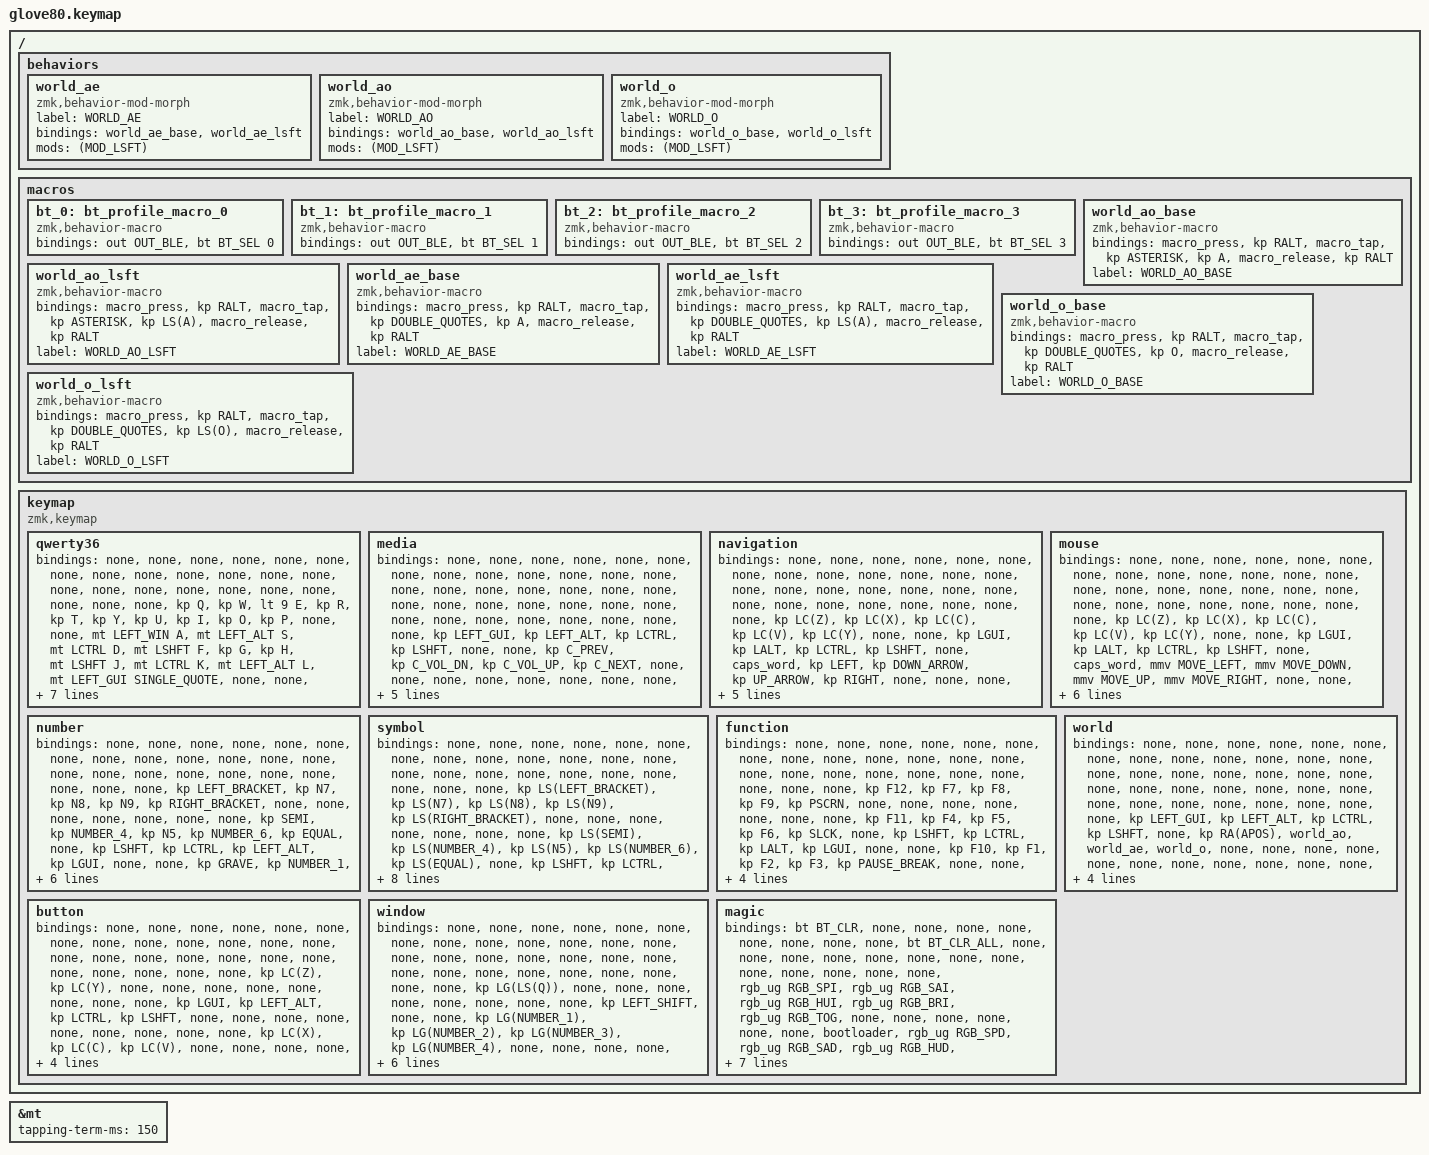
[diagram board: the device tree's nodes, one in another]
/*
 * Copyright (c) 2020 The ZMK Contributors
 *
 * SPDX-License-Identifier: MIT
 */

#include <behaviors.dtsi>
#include <dt-bindings/zmk/bt.h>
#include <dt-bindings/zmk/keys.h>
#include <dt-bindings/zmk/outputs.h>
#include <dt-bindings/zmk/pointing.h>
#include <dt-bindings/zmk/rgb.h>

// layers

#define DEFAULT 0
#define LOWER 1
#define MAGIC 2

&mt { tapping-term-ms = <150>; };

/ {
    behaviors {
        // For the "layer" key, it'd nice to be able to use it as either a shift or a toggle.
        // Configure it as a tap dance, so the first tap (or hold) is a &mo and the second tap is a &to

        world_ae: world_ae {
            compatible = "zmk,behavior-mod-morph";
            label = "WORLD_AE";
            bindings = <&world_ae_base>, <&world_ae_lsft>;

            #binding-cells = <0>;
            mods = <(MOD_LSFT)>;
        };

        world_ao: world_ao {
            compatible = "zmk,behavior-mod-morph";
            label = "WORLD_AO";
            bindings = <&world_ao_base>, <&world_ao_lsft>;

            #binding-cells = <0>;
            mods = <(MOD_LSFT)>;
        };

        world_o: world_o {
            compatible = "zmk,behavior-mod-morph";
            label = "WORLD_O";
            bindings = <&world_o_base>, <&world_o_lsft>;

            #binding-cells = <0>;
            mods = <(MOD_LSFT)>;
        };
    };

    macros {
        bt_0: bt_profile_macro_0 {
            compatible = "zmk,behavior-macro";
            #binding-cells = <0>;
            bindings = <&out OUT_BLE &bt BT_SEL 0>;
        };

        bt_1: bt_profile_macro_1 {
            compatible = "zmk,behavior-macro";
            #binding-cells = <0>;
            bindings = <&out OUT_BLE &bt BT_SEL 1>;
        };

        bt_2: bt_profile_macro_2 {
            compatible = "zmk,behavior-macro";
            #binding-cells = <0>;
            bindings = <&out OUT_BLE &bt BT_SEL 2>;
        };

        bt_3: bt_profile_macro_3 {
            compatible = "zmk,behavior-macro";
            #binding-cells = <0>;
            bindings = <&out OUT_BLE &bt BT_SEL 3>;
        };

        world_ao_base: world_ao_base {
            compatible = "zmk,behavior-macro";
            #binding-cells = <0>;
            bindings =
                <&macro_press>,
                <&kp RALT>,
                <&macro_tap>,
                <&kp ASTERISK &kp A>,
                <&macro_release>,
                <&kp RALT>;

            label = "WORLD_AO_BASE";
        };

        world_ao_lsft: world_ao_lsft {
            compatible = "zmk,behavior-macro";
            #binding-cells = <0>;
            bindings =
                <&macro_press>,
                <&kp RALT>,
                <&macro_tap>,
                <&kp ASTERISK &kp LS(A)>,
                <&macro_release>,
                <&kp RALT>;

            label = "WORLD_AO_LSFT";
        };

        world_ae_base: world_ae_base {
            compatible = "zmk,behavior-macro";
            #binding-cells = <0>;
            bindings =
                <&macro_press>,
                <&kp RALT>,
                <&macro_tap>,
                <&kp DOUBLE_QUOTES &kp A>,
                <&macro_release>,
                <&kp RALT>;

            label = "WORLD_AE_BASE";
        };

        world_ae_lsft: world_ae_lsft {
            compatible = "zmk,behavior-macro";
            #binding-cells = <0>;
            bindings =
                <&macro_press>,
                <&kp RALT>,
                <&macro_tap>,
                <&kp DOUBLE_QUOTES &kp LS(A)>,
                <&macro_release>,
                <&kp RALT>;

            label = "WORLD_AE_LSFT";
        };

        world_o_base: world_o_base {
            compatible = "zmk,behavior-macro";
            #binding-cells = <0>;
            bindings =
                <&macro_press>,
                <&kp RALT>,
                <&macro_tap>,
                <&kp DOUBLE_QUOTES &kp O>,
                <&macro_release>,
                <&kp RALT>;

            label = "WORLD_O_BASE";
        };

        world_o_lsft: world_o_lsft {
            compatible = "zmk,behavior-macro";
            #binding-cells = <0>;
            bindings =
                <&macro_press>,
                <&kp RALT>,
                <&macro_tap>,
                <&kp DOUBLE_QUOTES &kp LS(O)>,
                <&macro_release>,
                <&kp RALT>;

            label = "WORLD_O_LSFT";
        };
    };

    keymap {
        compatible = "zmk,keymap";

        qwerty36 {
            // ---------------------------------------------------------------------------------------------------------------------------------
            // |  F1   |  F2 |  F3 |  F4  |  F5  |                                                               |  F6   |  F7   |  F8  |   F9  |  F10 |
            // |  =    |  1  |  2  |  3   |  4   |  5   |                                                 |  6   |   7   |   8   |  9   |   0   |   -  |
            // |  TAB  |  Q  |  W  |  E   |  R   |  T   |                                                 |  Y   |   U   |   I   |  O   |   P   |   \  |
            // |  ESC  |  A  |  S  |  D   |  F   |  G   |                                                 |  H   |   J   |   K   |  L   |   ;   |   '  |
            // |   `   |  Z  |  X  |  C   |  V   |  B   | LSHFT | LCTRL | LOWER | | LGUI  | RCTRL | RSHFT |  N   |   M   |   ,   |  .   |   /   | PGUP |
            // | MAGIC | HOME| END | LEFT | RIGHT|      | BSPC  | DEL   | LALT  | | RALT  | RET   | SPACE |      |  UP   | DOWN  |  [   |   ]   | PGDN |

            bindings = <
&none   &none           &none           &none        &none                                                                                                       &none        &none        &none           &none                      &none
&none   &none           &none           &none        &none        &none                                                                                   &none  &none        &none        &none           &none                      &none
&none   &kp Q           &kp W           &lt 9 E      &kp R        &kp T                                                                                   &kp Y  &kp U        &kp I        &kp O           &kp P                      &none
&none   &mt LEFT_WIN A  &mt LEFT_ALT S  &mt LCTRL D  &mt LSHFT F  &kp G                                                                                   &kp H  &mt LSHFT J  &mt LCTRL K  &mt LEFT_ALT L  &mt LEFT_GUI SINGLE_QUOTE  &none
&none   &lt 8 Z         &kp X           &kp C        &kp V        &kp B  &none         &none            &none        &none        &none        &none      &kp N  &kp M        &kp COMMA    &kp DOT         &lt 7 SLASH                &none
&mo 10  &none           &none           &none        &none               &lt 1 ESCAPE  &lt 2 BACKSPACE  &lt 3 TAB    &lt 4 ENTER  &lt 5 SPACE  &lt 6 DEL         &none        &none        &none           &none                      &none
            >;
        };

        media {
            bindings = <
&none  &none         &none         &none      &none                                                                             &none       &none         &none         &none       &none
&none  &none         &none         &none      &none      &none                                                           &none  &none       &none         &none         &none       &none
&none  &none         &none         &none      &none      &none                                                           &none  &none       &none         &none         &none       &none
&none  &kp LEFT_GUI  &kp LEFT_ALT  &kp LCTRL  &kp LSHFT  &none                                                           &none  &kp C_PREV  &kp C_VOL_DN  &kp C_VOL_UP  &kp C_NEXT  &none
&none  &none         &none         &none      &none      &none  &none  &none  &none    &none       &none     &none       &none  &none       &none         &none         &none       &none
&none  &none         &none         &none      &none             &none  &none  &none    &kp C_STOP  &kp C_PP  &kp C_MUTE         &none       &none         &none         &none       &none
            >;
        };

        navigation {
            bindings = <
&none  &none     &none     &none      &none                                                                     &none      &none           &none         &none      &none
&none  &none     &none     &none      &none      &none                                              &none       &none      &none           &none         &none      &none
&none  &none     &none     &none      &none      &none                                              &kp LC(Z)   &kp LC(X)  &kp LC(C)       &kp LC(V)     &kp LC(Y)  &none
&none  &kp LGUI  &kp LALT  &kp LCTRL  &kp LSHFT  &none                                              &caps_word  &kp LEFT   &kp DOWN_ARROW  &kp UP_ARROW  &kp RIGHT  &none
&none  &none     &none     &none      &none      &none  &none  &none  &none    &none  &none  &none  &kp INS     &kp HOME   &kp PG_DN       &kp PG_UP     &kp END    &none
&none  &none     &none     &none      &none             &none  &none  &none    &none  &none  &none              &none      &none           &none         &none      &none
            >;
        };

        mouse {
            bindings = <
&none  &none     &none     &none      &none                                                                                 &none           &none           &none         &none            &none
&none  &none     &none     &none      &none      &none                                                          &none       &none           &none           &none         &none            &none
&none  &none     &none     &none      &none      &none                                                          &kp LC(Z)   &kp LC(X)       &kp LC(C)       &kp LC(V)     &kp LC(Y)        &none
&none  &kp LGUI  &kp LALT  &kp LCTRL  &kp LSHFT  &none                                                          &caps_word  &mmv MOVE_LEFT  &mmv MOVE_DOWN  &mmv MOVE_UP  &mmv MOVE_RIGHT  &none
&none  &none     &none     &none      &none      &none  &none  &none  &none    &none      &none      &none      &none       &msc SCRL_LEFT  &msc SCRL_DOWN  &msc SCRL_UP  &msc SCRL_RIGHT  &none
&none  &none     &none     &none      &none             &none  &none  &none    &mkp RCLK  &mkp LCLK  &mkp MCLK              &none           &none           &none         &none            &none
            >;
        };

        number {
            bindings = <
&none  &none             &none         &none         &none                                                                                      &none      &none      &none         &none     &none
&none  &none             &none         &none         &none         &none                                                                 &none  &none      &none      &none         &none     &none
&none  &kp LEFT_BRACKET  &kp N7        &kp N8        &kp N9        &kp RIGHT_BRACKET                                                     &none  &none      &none      &none         &none     &none
&none  &kp SEMI          &kp NUMBER_4  &kp N5        &kp NUMBER_6  &kp EQUAL                                                             &none  &kp LSHFT  &kp LCTRL  &kp LEFT_ALT  &kp LGUI  &none
&none  &kp GRAVE         &kp NUMBER_1  &kp NUMBER_2  &kp NUMBER_3  &kp BACKSLASH      &none    &none   &none        &none  &none  &none  &none  &none      &none      &none         &none     &none
&none  &none             &none         &none         &none                            &kp DOT  &kp N0  &kp MINUS    &none  &none  &none         &none      &none      &none         &none     &none
            >;
        };

        symbol {
            bindings = <
&none  &none                 &none             &none             &none                                                                                                         &none      &none      &none         &none     &none
&none  &none                 &none             &none             &none             &none                                                                                &none  &none      &none      &none         &none     &none
&none  &kp LS(LEFT_BRACKET)  &kp LS(N7)        &kp LS(N8)        &kp LS(N9)        &kp LS(RIGHT_BRACKET)                                                                &none  &none      &none      &none         &none     &none
&none  &kp LS(SEMI)          &kp LS(NUMBER_4)  &kp LS(N5)        &kp LS(NUMBER_6)  &kp LS(EQUAL)                                                                        &none  &kp LSHFT  &kp LCTRL  &kp LEFT_ALT  &kp LGUI  &none
&none  &kp LS(GRAVE)         &kp LS(NUMBER_1)  &kp LS(NUMBER_2)  &kp LS(NUMBER_3)  &kp LS(BACKSLASH)      &none       &none       &none            &none  &none  &none  &none  &none      &none      &none         &none     &none
&none  &none                 &none             &none             &none                                    &kp LS(N9)  &kp LS(N0)  &kp LS(MINUS)    &none  &none  &none         &none      &none      &none         &none     &none
            >;
        };

        function {
            bindings = <
&none  &none    &none   &none   &none                                                                                 &none      &none      &none     &none     &none
&none  &none    &none   &none   &none   &none                                                                  &none  &none      &none      &none     &none     &none
&none  &kp F12  &kp F7  &kp F8  &kp F9  &kp PSCRN                                                              &none  &none      &none      &none     &none     &none
&none  &kp F11  &kp F4  &kp F5  &kp F6  &kp SLCK                                                               &none  &kp LSHFT  &kp LCTRL  &kp LALT  &kp LGUI  &none
&none  &kp F10  &kp F1  &kp F2  &kp F3  &kp PAUSE_BREAK  &none      &none      &none      &none  &none  &none  &none  &none      &none      &none     &none     &none
&none  &none    &none   &none   &none                    &kp K_APP  &kp SPACE  &kp TAB    &none  &none  &none         &none      &none      &none     &none     &none
            >;
        };

        world {
            bindings = <
&none  &none         &none         &none      &none                                                                                      &none      &none      &none     &none  &none
&none  &none         &none         &none      &none      &none                                                             &none         &none      &none      &none     &none  &none
&none  &none         &none         &none      &none      &none                                                             &none         &none      &none      &none     &none  &none
&none  &kp LEFT_GUI  &kp LEFT_ALT  &kp LCTRL  &kp LSHFT  &none                                                             &kp RA(APOS)  &world_ao  &world_ae  &world_o  &none  &none
&none  &none         &none         &none      &none      &none  &none       &none          &none      &none  &none  &none  &none         &none      &none      &none     &none  &none
&none  &none         &none         &none      &none             &kp ESCAPE  &kp BACKSPACE  &kp TAB    &none  &none  &none                &none      &none      &none     &none  &none
            >;
        };

        button {
            bindings = <
&none  &none     &none         &none      &none                                                                            &none  &none  &none  &none  &none
&none  &none     &none         &none      &none      &none                                                          &none  &none  &none  &none  &none  &none
&none  &none     &none         &kp LC(Z)  &kp LC(Y)  &none                                                          &none  &none  &none  &none  &none  &none
&none  &kp LGUI  &kp LEFT_ALT  &kp LCTRL  &kp LSHFT  &none                                                          &none  &none  &none  &none  &none  &none
&none  &none     &kp LC(X)     &kp LC(C)  &kp LC(V)  &none  &none      &none      &none        &none  &none  &none  &none  &none  &none  &none  &none  &none
&none  &none     &none         &none      &none             &mkp MCLK  &mkp LCLK  &mkp RCLK    &none  &none  &none         &none  &none  &none  &none  &none
            >;
        };

        window {
            bindings = <
&none  &none  &none  &none  &none                                                                     &none             &none             &none             &none             &none
&none  &none  &none  &none  &none           &none                                              &none  &none             &none             &none             &none             &none
&none  &none  &none  &none  &none           &none                                              &none  &kp LG(LS(Q))     &none             &none             &none             &none
&none  &none  &none  &none  &kp LEFT_SHIFT  &none                                              &none  &kp LG(NUMBER_1)  &kp LG(NUMBER_2)  &kp LG(NUMBER_3)  &kp LG(NUMBER_4)  &none
&none  &none  &none  &none  &none           &none  &none  &none  &none    &none  &none  &none  &none  &kp LG(N5)        &kp LG(NUMBER_6)  &kp LG(N7)        &kp LG(N8)        &none
&none  &none  &none  &none  &none                  &none  &none  &none    &none  &none  &none         &none             &none             &none             &none             &none
            >;
        };

        magic {
            bindings = <
&bt BT_CLR   &none            &none            &none            &none                                                                                       &none  &none  &none  &none  &bt BT_CLR_ALL
&none        &none            &none            &none            &none            &none                                                               &none  &none  &none  &none  &none  &none
&none        &rgb_ug RGB_SPI  &rgb_ug RGB_SAI  &rgb_ug RGB_HUI  &rgb_ug RGB_BRI  &rgb_ug RGB_TOG                                                     &none  &none  &none  &none  &none  &none
&bootloader  &rgb_ug RGB_SPD  &rgb_ug RGB_SAD  &rgb_ug RGB_HUD  &rgb_ug RGB_BRD  &rgb_ug RGB_EFF                                                     &none  &none  &none  &none  &none  &bootloader
&sys_reset   &none            &none            &none            &none            &none            &bt_2  &bt_3  &none           &none  &none  &none  &none  &none  &none  &none  &none  &sys_reset
&none        &none            &none            &none            &none                             &bt_0  &bt_1  &out OUT_USB    &none  &none  &none         &none  &none  &none  &none  &none
            >;
        };
    };
};
